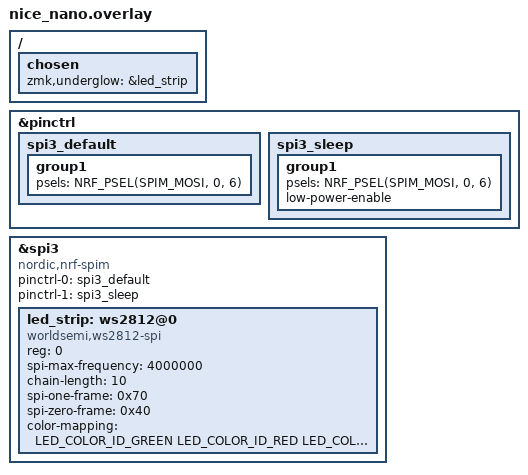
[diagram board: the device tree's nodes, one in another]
#include <dt-bindings/led/led.h>

// Firmware with alternative pins
//
// The #ifndef statement can safely be removed. It's only used in the example
// zmk-config repo to create an additional firmware with alternative PIN
// assignments, but since the alternative pins conflict with the underglow
// pins, we disable it here.
//
// You can leave it or remove in your own zmk config. If you remove it, you
// should also remove the entry in `zmk-config-example/build.yaml` that uses
// it.

#ifndef MOUSE_PS2_ALT_PINS

&pinctrl {
    spi3_default: spi3_default {
        group1 {
            psels = <NRF_PSEL(SPIM_MOSI, 0, 6)>;
        };
    };

    spi3_sleep: spi3_sleep {
        group1 {
            psels = <NRF_PSEL(SPIM_MOSI, 0, 6)>;
            low-power-enable;
        };
    };
};

&spi3 {
    compatible = "nordic,nrf-spim";
    status = "okay";

    pinctrl-0 = <&spi3_default>;
    pinctrl-1 = <&spi3_sleep>;
    pinctrl-names = "default", "sleep";

    led_strip: ws2812@0 {
        compatible = "worldsemi,ws2812-spi";

        /* SPI */
        reg = <0>; /* ignored, but necessary for SPI bindings */
        spi-max-frequency = <4000000>;

        /* WS2812 */
        chain-length = <10>; /* arbitrary; change at will */
        spi-one-frame = <0x70>;
        spi-zero-frame = <0x40>;

        color-mapping = <LED_COLOR_ID_GREEN LED_COLOR_ID_RED LED_COLOR_ID_BLUE>;
    };
};

/ {
    chosen {
        zmk,underglow = &led_strip;
    };
};

#endif  // MOUSE_PS2_ALT_PINS
